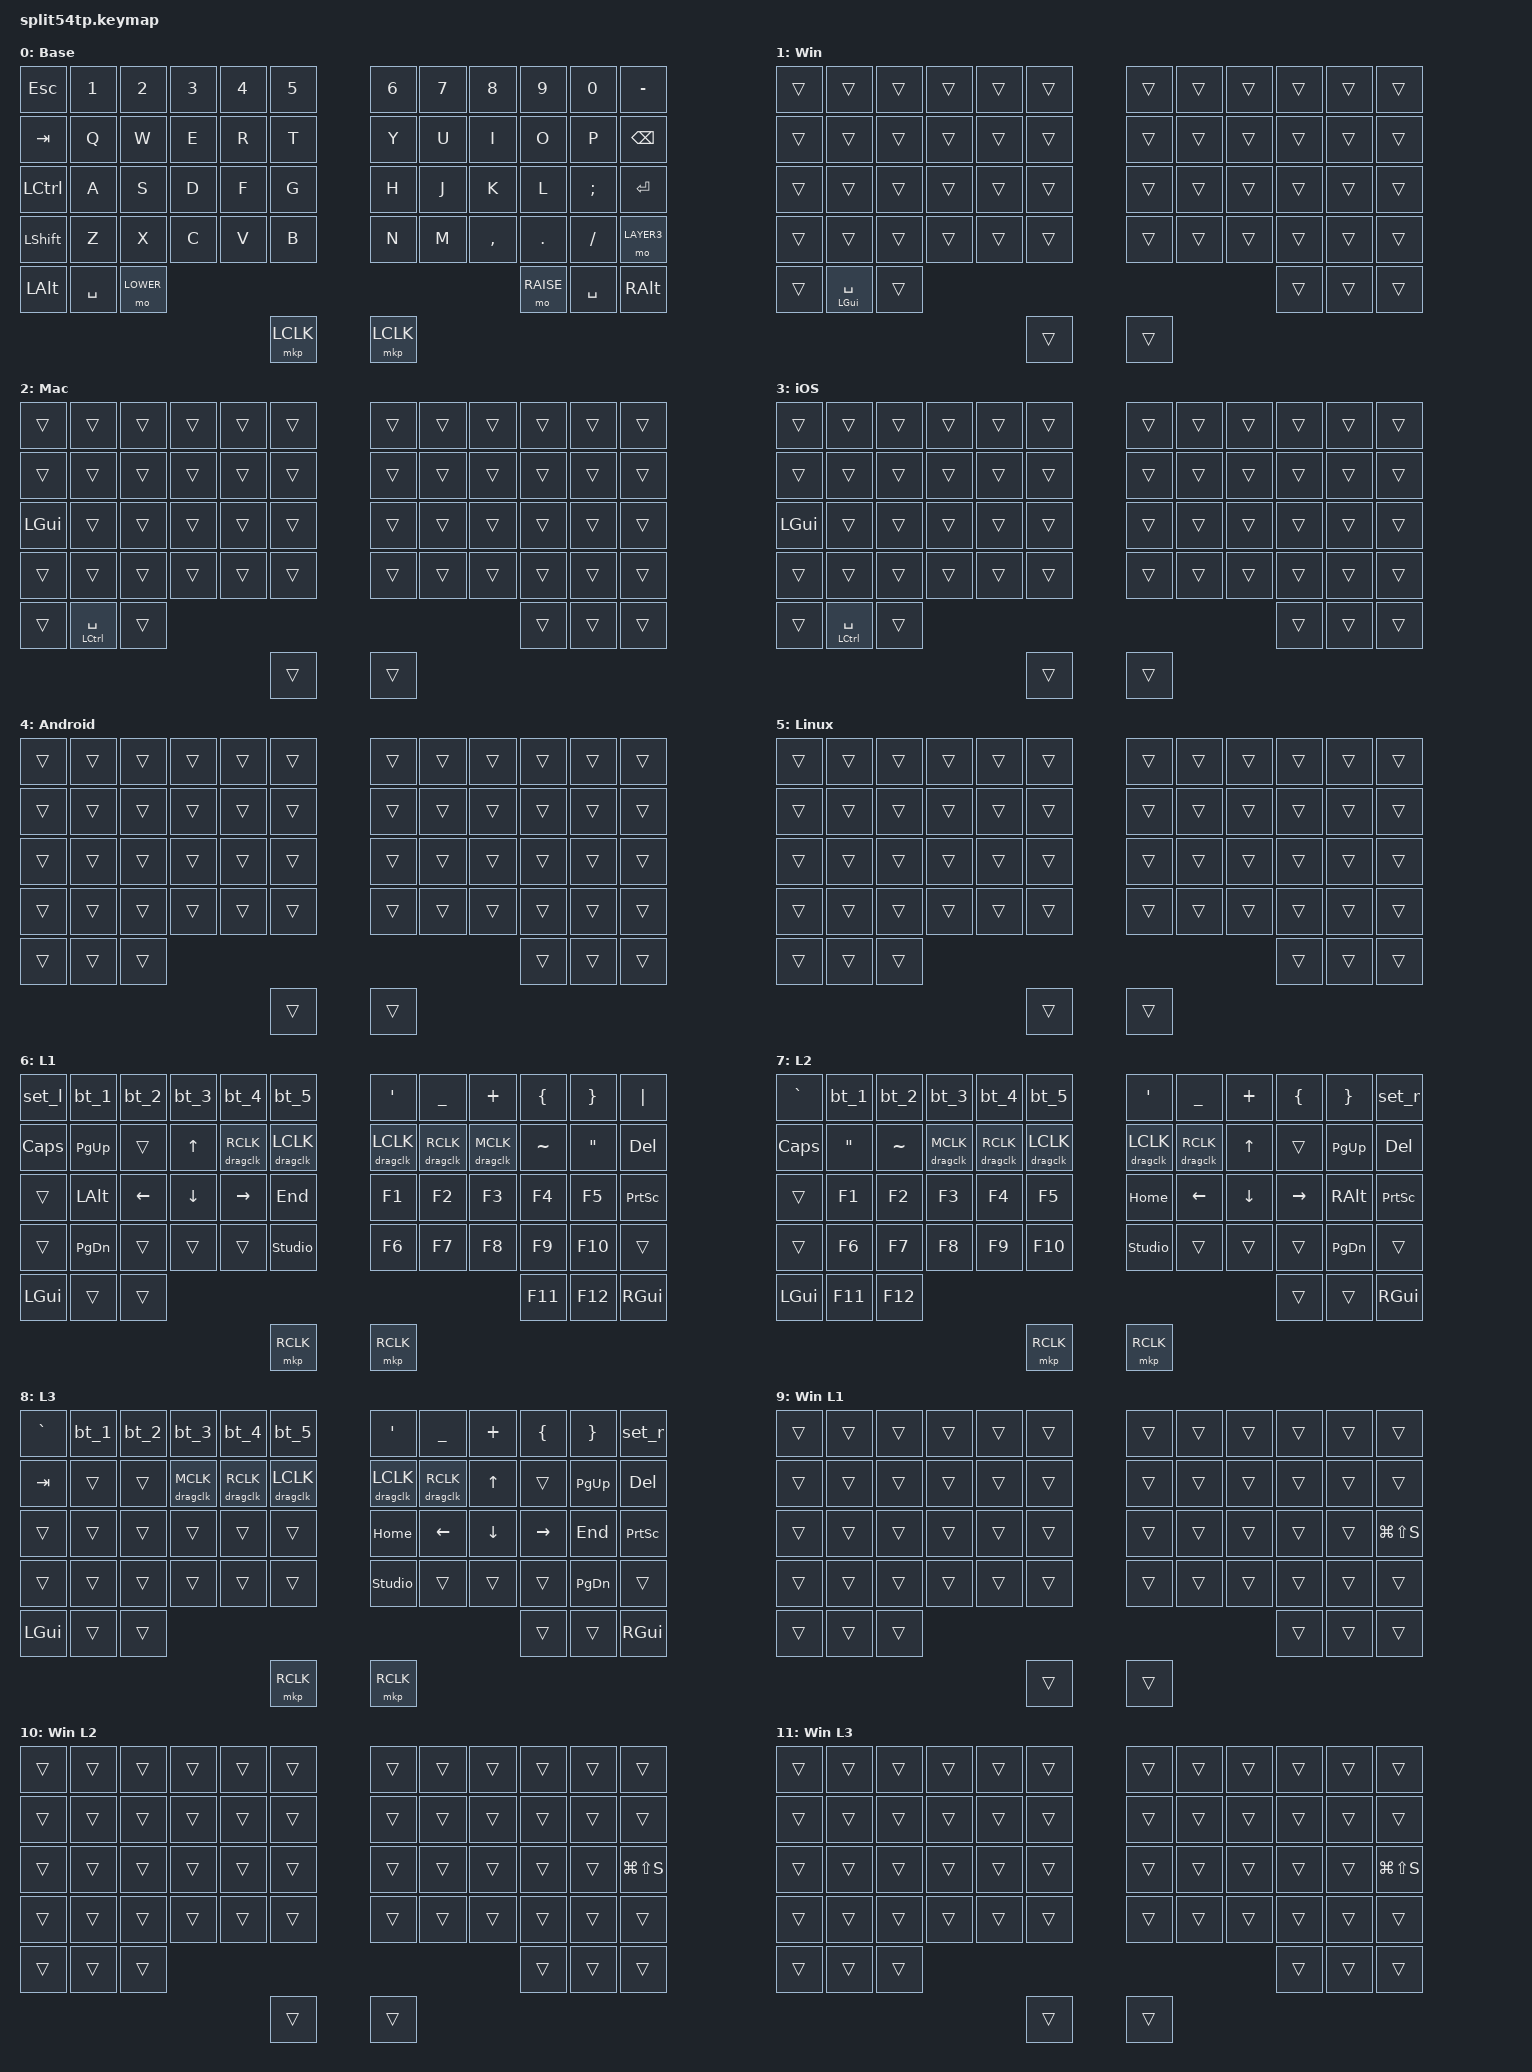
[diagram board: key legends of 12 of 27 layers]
/*
 * split54tp デフォルトキーマップ (US配列 / 手書きレイアウト図準拠)
 * 54キー + ホイールエンコーダのプッシュ2 = 56ポジション
 *
 *  ┌─────┬─────┬─────┬─────┬─────┬─────┐   ┌─────┬─────┬─────┬─────┬─────┬─────┐
 *  │ ESC │  1  │  2  │  3  │  4  │  5  │   │  6  │  7  │  8  │  9  │  0  │  -  │  (2026-11-01: DEL → -。DEL は L1 + BS)
 *  ├─────┼─────┼─────┼─────┼─────┼─────┤   ├─────┼─────┼─────┼─────┼─────┼─────┤
 *  │ TAB │  Q  │  W  │  E  │  R  │  T  │   │  Y  │  U  │  I  │  O  │  P  │ BS  │
 *  ├─────┼─────┼─────┼─────┼─────┼─────┤ ◉ ├─────┼─────┼─────┼─────┼─────┼─────┤  ◉=スティック
 *  │CTRL │  A  │  S  │  D  │  F  │  G  │   │  H  │  J  │  K  │  L  │  ;  │ ENT │
 *  ├─────┼─────┼─────┼─────┼─────┼─────┤ ≡ ├─────┼─────┼─────┼─────┼─────┼─────┤  ≡=スクロールホイール
 *  │SHIFT│  Z  │  X  │  C  │  V  │  B  │   │  N  │  M  │  ,  │  .  │  /  │SHIFT│
 *  └─────┴─────┴─────┼─────┼─────┼─────┤   ├─────┼─────┼─────┼─────┴─────┴─────┘
 *                    │ALT  │SPC  │ L1  │   │ L2  │SPC  │ALT  │
 *                    └─────┴─────┴─────┘   └─────┴─────┴─────┘
 *
 * ★ ZMK Studio 対応ビルドです (右=セントラルのみ)。
 *   https://zmk.studio/ に接続すると、再ビルドなしでキー割当を変更できます。
 *   変更するには、まず &studio_unlock を押してロックを解除します。
 *     L1 + B の位置 … 左半身  (2026-11-15 変更。前は L2 + Tab の位置)
 *     L2 + N の位置 … 右半身  (2026-11-15 変更。前は L2 + BS の位置。L3 + N でも同じ)
 *     L2 の Tab / BS の位置は Del になった (2026-11-15、ユーザー指定)
 *     ゴースト (2026-11-15 配線表から計算、2 キー同時。L1 / L2 の親指はゴーストが立たない位置):
 *       B (Studio解除) が立つのは 1 + D・2 + C、N が立つのは , + 9・0 + K、Tab (Del) は 1 + Z、BS (Del) は / + 0 (どれもふだん同時に押さない)。
 *       B・N・Tab・BS をほかのキーと一緒に押して立つものに、書き換え・ペアリング・BT 消去はない。
 *   ⚠ 2026-11-15 レイヤーの数と並びを変えた (7 → 27 枚)。Studio で保存したことがあれば、Studio の "Restore Stock Settings" を実行すること。
 *   ⚠ 切断するか、Studio上で一定時間操作しないと再びロックされる。
 *     https://zmk.dev/docs/keymaps/behaviors/studio-unlock
 *
 *   ⚠ 一度 Studio でキーマップを保存すると、このファイルへの変更は反映されなくなります。
 *     戻すには Studio の "Restore Stock Settings" を実行してください。
 *     以降、このファイルは「初期値」と「Studioで使えるレイヤー枠」を決めるものになります。
 *
 * ★ ファームウェア書き換え用のキー (2026-08-31 追加 / 2026-11-01 左右とも変更 / 2026-11-04 設定レイヤーへ移動)
 *     設定レイヤーの X (左手だけ) → 左半身をブートローダへ
 *     設定レイヤーの . (右手だけ) → 右半身をブートローダへ
 *   ⚠ キーマップは右で処理するので、左の書き換えにも右の電源と左右の接続が要る。
 *     https://zmk.dev/docs/features/split-keyboards
 *
 * ★ 設定レイヤー (2026-11-04 追加。下の settings_layer)
 *   書き換え・TP 校正・TP 感度・BT 消去・USB / BT 出力の切り替えをまとめた。
 *   片側が使えなくても、もう片側だけで入って設定できるように左右に同じものを置いた。
 *     入る: 左 = L1 + Shift + Esc の位置 / 右 = L2 + Shift + - の位置 (Shift を押していなければ今までどおり ` / |)
 *       ★ 2026-11-15 右 Shift の位置は L3 になった。右手だけなら L2 + L3 (右 Shift の位置) + - (同じ指の動き)
 *     出る: L1 / L2 / 左 Ctrl / Enter のどれかを押す
 *   入ったままになる (&tog)。ほかのキーは何もしない (&none) ので、文字が打てなければ設定レイヤーにいる。
 *   OLED のレイヤー名は "Set"。

 * ★★ チャーリープレックスのゴースト (2026-09-12 実機で確定) ★★
 *
 *   内側親指 RC(5,6) を押している間、sense線5のキー (7/U/J/M) を押すと
 *   ダイオードが直列につながり、sense線6の同じ行 (6/Y/H/N) が
 *   「押された」ことになる。逆に drive線6のキー (9/O/L/.) を押すと
 *   (0/P/;//) が立つ。これは電気的な制約でファームでは直せない。
 *
 *   実害の例: L2 + M → ゴーストで N が立ち、旧配置の &bootloader が発火して
 *             右半身がブートローダに入る (2026-09-12 に3時間を費やした)
 *             L2 + J → ← に加えて H の右クリックが出る (現在も再現する)
 *
 *   【原則】内側親指と併用するレイヤーでは、次の8か所に
 *           破壊的な操作やマウスクリックを置かないこと。
 *             6 / Y / H / N  (右・global col 13)
 *             0 / P / ; / /  (右)
 *           左半身も対称に 5 / T / G / B と同等の位置が該当する。
 *
 *   【ゴースト非対象の安全な位置】(内側親指と併用しても幽霊が立たない)
 *             右: I, BSPC, ,(カンマ), 右Shift
 *           → &bootloader と &studio_unlock はここへ逃がしてある。
 *
 *   rev.6 では親指キーとメイン列の電気的マッピングを見直すこと (最重要課題)。
 *
 *   ★ 2026-09-26 rev.6 で解決: 配線割当を見直し、保持キー併用時のゴーストは
 *     すべて未使用ペアに落ちる (実機で確認)。L1/L2 の &none 退避を撤去し、
 *     ゴースト対策前 (split54tp.keymap.bak4-20260912) の配置に戻した。
 *     &bootloader(L2+BSPC) / &studio_unlock(L2+Shift) の位置は bak4 のまま。
 *     上記の説明は rev.5 の記録として残す。
 *
 *   ZMK公式: リセット系ビヘイビアは「押した側」にだけ作用する (source-specific)。
 *   そのため左右それぞれにキーが必要。コンボにすると常にセントラル(右)側で
 *   実行されてしまうため、通常のキーとして両側に置いている。
 *   https://zmk.dev/docs/keymaps/behaviors/reset
 *
 *   ⚠ これはファームが正常に起動し、キーが反応する場合にのみ使える。
 *     起動しない / 配線ミスで反応しない場合は、XIAO のリセットボタンを
 *     素早く2回押す (ハードウェア側の最後の砦)。
 *
 * エンコーダは横軸のスクロールホイール(マウスホイール方式)。
 * ※ エンコーダへの behavior 割当は ZMK Studio では未対応のため、ここで定義します。
 * 回転はマウスのホイールスクロールとして送出する (&msc SCRL_UP / SCRL_DOWN)。
 * スクロール方向が逆の場合は enc_scroll の bindings を入れ替える。
 */

#include <behaviors.dtsi>
#include <dt-bindings/zmk/keys.h>
#include <dt-bindings/zmk/bt.h>
/*
 * ★ マウススクロールの速度 (既定: 10)
 *   &msc は押下時間に比例して積算する速度ベースの挙動。エンコーダは
 *   press→release が一瞬なので、既定値のままだと積算量がほぼ0になり動かない。
 *   下の scroll_dn / scroll_up マクロのホールド時間とセットで調整する。
 *   https://zmk.dev/docs/keymaps/behaviors/mouse-emulation
 */
#define ZMK_POINTING_DEFAULT_SCRL_VAL 80
#include <dt-bindings/zmk/pointing.h>
#include <dt-bindings/zmk/outputs.h>
#include <dt-bindings/zmk/modifiers.h>

/*
 * ★ 2026-10-31 LPPS の強制キャリブレーション (L2 + / に割当。2026-11-01 に . から移動)
 *   押すと、次に MOTION が来たときにドライバがレジスタ 0x04 に 1 を書く。そのときにスティックに触っていないこと。
 *   セントラル (右) で実行されるので、効くのは右の LPPS だけ。
 *   https://github.com/sekigon-gonnoc/zmk-driver-lpps
 *
 * ★ 2026-11-04 ドライバの &ps_calib をやめ、自作の &tpcalib (押した側の LPPS を校正) に替えた。
 *   設定レイヤーの Z (左) / / (右)。中身はドライバと同じ (lpps_request_write) で、実行する半身だけが違う。
 *   zmk-config の src/behaviors/behavior_tp_calib_local.c。左のファームにも入るので、左も書き直すこと。
 *   そのため lpps-calibration.dtsi は読み込まない。
 */

/*
 * ---- レイヤー構成 ----
 *  ZMKには「BLEプロファイルごとのキーマップ」機能は存在しない。
 *  レイヤーは全プロファイル共通なので、"プロファイル切替と同時にOS用の
 *  ベースレイヤーへ移動する" マクロを組んで等価の運用を実現する。
 *
 *  &to は「デフォルトレイヤー以外を全て無効化」する仕様なので、
 *  OS別レイヤーは差分(修飾キーの入れ替え)だけを書き、
 *  残りは &trans にしてレイヤー0を透過させればよい。
 *  https://zmk.dev/docs/keymaps/behaviors/layers
 */
/*
 * ★ 2026-11-01 OS 別のレイヤーを L1 / L2 より小さい番号に変更。
 *   番号が大きいレイヤーが優先されるので、Mac / iPad が上だと L2 + 左 Space (F11) や
 *   L1 / L2 のホイールが Mac / iPad の設定に隠れる。番号は下の keymap ノードの並びと合わせること。
 *   https://zmk.dev/docs/keymaps
 */
/*
 * ★ 2026-11-15 OS を 5 つに (ユーザー指定: Mac / Windows / iOS (iPad から改名) / Android / Linux、BT も 5 つ)。
 *   形は「共通 + OS ごとの差分」(ユーザーが選択): Base / L1 / L2 / L3 は全 OS 共通の 1 組。
 *   OS ごとに違うキーだけを、その OS のレイヤー (Base の差分) と「OS の L1 / L2 / L3」(L1〜L3 の差分) に書く。
 *   差分のレイヤーは &trans ばかりで、違うキーだけを書く。Studio でも OS ごとに変えられる。
 *   「OS の L1」などは条件付きレイヤー (下の conditional_layers) で、その OS と L1 の両方が有効な間だけ重なる。
 *     https://zmk.dev/docs/keymaps/conditional-layers
 *   BT1〜5 と OS は 1 対 1 (今は。ユーザーは将来、接続先と OS を別に選びたい):
 *     BT1 = Mac / BT2 = Windows / BT3 = iOS / BT4 = Android / BT5 = Linux
 *   OS のレイヤーは Ctrl + 1〜5 (L1 / L2 / L3) とペアリングのキー (設定レイヤー) で切り替わるほか、
 *   選んでいる BT の相手とつながったときにも自動で合わせる (下の os_layers と src/os_layers.c)。
 *   電源を入れた直後は Base だけで、相手とつながると、その OS のレイヤーになる。
 *   番号 (= 下の keymap ノードの並び) を変えたら、split54tp_right.overlay の tp_scroll / tp_drag の layers も直すこと。
 */
#define BASE     0   // 共通の Base (どの OS のレイヤーも重なっていないとき = 電源を入れてから相手とつながるまで)
#define WIN      1   // Windows : 左 Space の長押し → Win (2026-11-15)。ほかは Base のまま
#define MAC      2   // Mac     : 左 CTRL の位置 → CMD、左 Space の長押し → CTRL
#define IOS      3   // iOS     : Mac と同じ配列 (2026-11-15 iPad から改名)
#define ANDROID  4   // Android : 今は差分なし (Base のまま)
#define LINUX    5   // Linux   : 今は差分なし (Base のまま)
#define LOWER    6   // L1
#define RAISE    7   // L2
#define LAYER3   8   // L3 (2026-11-15 右 Shift の位置を押している間。中身は L2 から F1〜F12 を除いたもの)
#define WIN_L1   9   // ここから 23 までは「OS の L1 / L2 / L3」(条件付きレイヤー)
#define WIN_L2  10
#define WIN_L3  11
#define MAC_L1  12
#define MAC_L2  13
#define MAC_L3  14
#define IOS_L1  15
#define IOS_L2  16
#define IOS_L3  17
#define AND_L1  18
#define AND_L2  19
#define AND_L3  20
#define LNX_L1  21
#define LNX_L2  22
#define LNX_L3  23
#define SETENT  24   // L2 + L3 を押している間 (条件付き)。- の位置で設定レイヤーへ (右手だけで入るため。前は L2 + 右 Shift + -)
#define SETTINGS 25  // 設定レイヤー (2026-11-04)。L1〜L3 より上に置き、入っている間は L1〜L3 より優先する
#define DRAG    26   // ★ 2026-11-15 ドラッグ (L1〜L3 のクリックを押している間だけ重なる。中身はすべて &trans)。
                     //   番号は split54tp_right.overlay の tp_drag の layers と合わせること

// &tps_l / &tps_r (TP 感度) の引数 (src/behaviors/behavior_tp_speed.c と合わせる)
#define TPS_DN  0   // 1 段下げる
#define TPS_UP  1   // 1 段上げる
#define TPS_DEF 2   // 既定 (100%) に戻す

/ {
    behaviors {
        /*
         * ---- BLEプロファイル切替 (CTRL + 数字キー) ----
         * ベースの 1/2/3/4 の位置に置く。レイヤー(L1/L2)上で
         *   そのまま押す        → 記号 ( - = [ ] )
         *   CTRLを押しながら    → BLEプロファイル 1〜4 に切替/ペアリング
         * keep-mods は既定の0なので、数字キーを押している間は CTRL を外した報告になる。
         * ただし CTRL を押した時点の「CTRL を押した」という報告は、そのときのホストへもう送られている
         * (2026-11-15 訂正。前は「CTRLはホストへ送出されない」と書いていた)。
         * https://zmk.dev/docs/keymaps/behaviors/mod-morph
         *
         * ZMKは既定で5プロファイルを持つ (右 = セントラルは BT_MAX_PAIRED 6 − 左 1)。
         * ★ 2026-11-15 4 つ → 5 つ全部を使う (5 の位置 = BT5。Ctrl なしは今までどおり \)。
         * https://zmk.dev/docs/features/bluetooth#profiles
         */
        /*
         * プロファイル切替 = BLEプロファイル選択 + OS用ベースレイヤーへ移動
         *   1: Mac  / 2: Windows(会社PC) / 3: iOS / 4: Android / 5: Linux (2026-11-15。前は 3: iPad / 4: 予備 (Windows 配列))
         *
         * ★ 2026-11-15 切り替える前に、元のホストへ「CTRL を離した」を送る
         *   (ユーザー: Windows でスクロールがズームになり、ほかのマウスでも同じ。Windows の再起動で直る)。
         *   ZMK (641514a) はプロファイルを切り替えるとき、押しているキーを全部離した報告を送るが、
         *   app/src/ble.c の zmk_ble_prof_select() が先に active_profile を新しい番号に変えてから知らせるので、
         *   app/src/hog.c は zmk_ble_active_profile_conn() = 新しいホストへ送る。元のホストには
         *   「CTRL を押した」だけが残り、元のホストでは CTRL を押したままに見える (CTRL + ホイール = ズーム)。
         *   そこで、まだ元のホストを向いているうちに LCTRL を離し、wait-ms (30ms) の間に送らせてから切り替える。
         *   このあと指で CTRL を離しても、ZMK は「もう離してある」として何も送らない (app/src/hid.c)。
         *   続けて別の番号へ切り替えるときは、CTRL を押し直す。
         *   CTRL は左 CTRL (BASE) と、Mac / iPad の左 Space 長押し (&ctl_spc LCTRL) の 2 つで、どちらも LCTRL。
         *   https://zmk.dev/docs/keymaps/behaviors/macros
         * ★ 2026-11-21 Mac / iOS の L1 では Cmd + 1〜5 でも切り替える (下の btm_1〜btm_5、ユーザー指定)。
         *   そのため LCTRL に加えて LGUI / RGUI も離してから切り替える (Cmd も元のホストで押したままに見えないように)。
         *   押していない修飾キーを離しても、ZMK は何も送らない (app/src/hid.c が「押されていない」として報告を作らない)。
         */
        prof1_mac: prof1_mac {
            compatible = "zmk,behavior-macro";
            #binding-cells = <0>;
            wait-ms = <30>;
            bindings = <&macro_release &kp LCTRL &kp LGUI &kp RGUI>, <&macro_tap &bt BT_SEL 0 &to MAC>;
        };
        prof2_win: prof2_win {
            compatible = "zmk,behavior-macro";
            #binding-cells = <0>;
            wait-ms = <30>;
            bindings = <&macro_release &kp LCTRL &kp LGUI &kp RGUI>, <&macro_tap &bt BT_SEL 1 &to WIN>;   // 2026-11-15 BASE → WIN
        };
        prof3_ios: prof3_ios {
            compatible = "zmk,behavior-macro";
            #binding-cells = <0>;
            wait-ms = <30>;
            bindings = <&macro_release &kp LCTRL &kp LGUI &kp RGUI>, <&macro_tap &bt BT_SEL 2 &to IOS>;
        };
        prof4_android: prof4_android {
            compatible = "zmk,behavior-macro";
            #binding-cells = <0>;
            wait-ms = <30>;
            bindings = <&macro_release &kp LCTRL &kp LGUI &kp RGUI>, <&macro_tap &bt BT_SEL 3 &to ANDROID>;   // 2026-11-15 予備 (BASE) → Android
        };
        prof5_linux: prof5_linux {
            compatible = "zmk,behavior-macro";
            #binding-cells = <0>;
            wait-ms = <30>;
            bindings = <&macro_release &kp LCTRL &kp LGUI &kp RGUI>, <&macro_tap &bt BT_SEL 4 &to LINUX>;   // 2026-11-15 追加
        };

        /*
         * ★ 2026-11-11 ボタン一つでペアリング (ユーザー指定)。設定レイヤーの 左 1〜4 / 右 6〜9 = BT1〜BT4。
         *   ★ 2026-11-15 BT5 (Linux) を追加: 左 5 / 右 0。
         *   出力を BT にする → その番号を選ぶ → その番号の登録を消す (ペアリング待ちになる) → その OS のレイヤーへ。
         *   &to で設定レイヤーから出る。OLED は「BTn ⚙」(歯車 = ペアリング待ち)。相手の機器でも古い登録を消してからペアリングする。
         *   ⚠ 押すとその番号の登録が消える (ほかの番号と、左右の間の接続は消えない)。
         *   https://zmk.dev/docs/keymaps/behaviors/bluetooth / https://zmk.dev/docs/keymaps/behaviors/outputs
         */
        /*
         * ★ 2026-11-15 ドラッグできるクリック (ユーザー: 「左クリックし続けた状態で TP を触っても全く動かない」)。
         *   L1 / L2 を押している間はスティックがスクロールになる (split54tp_right.overlay の tp_scroll / tp_hscroll) ので、
         *   L1 / L2 のクリックを押したままスティックを倒しても、カーソルが動かなかった。
         *   押している間だけ DRAG レイヤーを重ねてクリックも押したままにし、離したら両方離す。
         *   split54tp_right.overlay の tp_drag (DRAG のときはカーソル) を tp_scroll / tp_hscroll より前に書いてあるので、
         *   ZMK は先に当てはまった tp_drag を使い、tp_scroll / tp_hscroll は使わない (app/src/pointing/input_listener.c)。
         *   ★ 2026-11-21 スクロールは、押したキーと同じ側のスティック = 上下、反対側 = 左右 (tp_hscroll を追加。rev7-修正計画.md 手順 249)。
         *   使い方: &dragclk LCLK / RCLK / MCLK。https://zmk.dev/docs/keymaps/behaviors/macros
         */
        dragclk: dragclk {
            compatible = "zmk,behavior-macro-one-param";
            #binding-cells = <1>;
            wait-ms = <0>;
            tap-ms = <0>;
            bindings
                = <&macro_press &mo DRAG>
                , <&macro_param_1to1>
                , <&macro_press &mkp MACRO_PLACEHOLDER>
                , <&macro_pause_for_release>
                , <&macro_param_1to1>
                , <&macro_release &mkp MACRO_PLACEHOLDER>
                , <&macro_release &mo DRAG>
                ;
        };

        pair1: pair1 {
            compatible = "zmk,behavior-macro";
            #binding-cells = <0>;
            bindings = <&out OUT_BLE>, <&bt BT_SEL 0>, <&bt BT_CLR>, <&to MAC>;
        };
        pair2: pair2 {
            compatible = "zmk,behavior-macro";
            #binding-cells = <0>;
            bindings = <&out OUT_BLE>, <&bt BT_SEL 1>, <&bt BT_CLR>, <&to WIN>;   // 2026-11-15 BASE → WIN
        };
        pair3: pair3 {
            compatible = "zmk,behavior-macro";
            #binding-cells = <0>;
            bindings = <&out OUT_BLE>, <&bt BT_SEL 2>, <&bt BT_CLR>, <&to IOS>;
        };
        pair4: pair4 {
            compatible = "zmk,behavior-macro";
            #binding-cells = <0>;
            bindings = <&out OUT_BLE>, <&bt BT_SEL 3>, <&bt BT_CLR>, <&to ANDROID>;   // 2026-11-15 BASE → ANDROID
        };
        pair5: pair5 {   // 2026-11-15 追加 (BT5 = Linux)
            compatible = "zmk,behavior-macro";
            #binding-cells = <0>;
            bindings = <&out OUT_BLE>, <&bt BT_SEL 4>, <&bt BT_CLR>, <&to LINUX>;
        };

        bt_1: bt_1 {
            compatible = "zmk,behavior-mod-morph";
            #binding-cells = <0>;
            bindings = <&kp MINUS>, <&prof1_mac>;
            mods = <(MOD_LCTL|MOD_RCTL)>;
        };
        bt_2: bt_2 {
            compatible = "zmk,behavior-mod-morph";
            #binding-cells = <0>;
            bindings = <&kp EQUAL>, <&prof2_win>;
            mods = <(MOD_LCTL|MOD_RCTL)>;
        };
        bt_3: bt_3 {
            compatible = "zmk,behavior-mod-morph";
            #binding-cells = <0>;
            bindings = <&kp LBKT>, <&prof3_ios>;
            mods = <(MOD_LCTL|MOD_RCTL)>;
        };
        bt_4: bt_4 {
            compatible = "zmk,behavior-mod-morph";
            #binding-cells = <0>;
            bindings = <&kp RBKT>, <&prof4_android>;
            mods = <(MOD_LCTL|MOD_RCTL)>;
        };
        bt_5: bt_5 {   // 2026-11-15 追加。5 の位置 (Ctrl なしは今までどおり \)
            compatible = "zmk,behavior-mod-morph";
            #binding-cells = <0>;
            bindings = <&kp BSLH>, <&prof5_linux>;
            mods = <(MOD_LCTL|MOD_RCTL)>;
        };

        /*
         * ★ 2026-11-21 Mac / iOS の L1 だけ: Ctrl でも Cmd でも BT を切り替える (ユーザー指定)。
         *   ユーザー: Mac / iOS から他の OS へ切り替えるとき、Ctrl は左 Space の長押しなので L1 と一緒に押すのが手間。
         *   Mac / iOS では左 CTRL の位置が Cmd (LGUI) なので、L1 + Cmd + 1〜5 で切り替えられるようにした。
         *   置くのは mac_l1_layer / ios_l1_layer の 1〜5 の位置だけ (L1 の bt_1〜bt_5 の上に重なる)。
         *   ⚠ Mac / iOS の L1 では Cmd + - = [ ] \ (縮小・拡大・戻る・進むなど) は送れない。L2 / L3 + Cmd + 1〜5 では今までどおり送る
         *     (ユーザーが「L1 だけ変える」を選んだ)。Windows / Android / Linux は今までどおり (Ctrl だけ)。
         *   切り替えの中身は prof1_mac〜prof5_linux と同じ (LCTRL / LGUI / RGUI を離してから切り替える)。
         *   https://zmk.dev/docs/keymaps/behaviors/mod-morph
         */
        btm_1: btm_1 {
            compatible = "zmk,behavior-mod-morph";
            #binding-cells = <0>;
            bindings = <&kp MINUS>, <&prof1_mac>;
            mods = <(MOD_LCTL|MOD_RCTL|MOD_LGUI|MOD_RGUI)>;
        };
        btm_2: btm_2 {
            compatible = "zmk,behavior-mod-morph";
            #binding-cells = <0>;
            bindings = <&kp EQUAL>, <&prof2_win>;
            mods = <(MOD_LCTL|MOD_RCTL|MOD_LGUI|MOD_RGUI)>;
        };
        btm_3: btm_3 {
            compatible = "zmk,behavior-mod-morph";
            #binding-cells = <0>;
            bindings = <&kp LBKT>, <&prof3_ios>;
            mods = <(MOD_LCTL|MOD_RCTL|MOD_LGUI|MOD_RGUI)>;
        };
        btm_4: btm_4 {
            compatible = "zmk,behavior-mod-morph";
            #binding-cells = <0>;
            bindings = <&kp RBKT>, <&prof4_android>;
            mods = <(MOD_LCTL|MOD_RCTL|MOD_LGUI|MOD_RGUI)>;
        };
        btm_5: btm_5 {
            compatible = "zmk,behavior-mod-morph";
            #binding-cells = <0>;
            bindings = <&kp BSLH>, <&prof5_linux>;
            mods = <(MOD_LCTL|MOD_RCTL|MOD_LGUI|MOD_RGUI)>;
        };

        /*
         * ★ 2026-11-01 Mac / iPad の左 Space: 短く押すと Space、約 0.2 秒以上押すと CTRL
         *   Mac / iPad レイヤーは左 CTRL の位置が CMD になり CTRL が無くなるので、ここに置く。
         *   プロファイルの切り替えも、左 Space の長押し + L2 + 1〜4 でできる（L1 は同じ親指なので押せない）。
         *   ★ 2026-11-21 Mac / iOS では L1 + Cmd (左 CTRL の位置) + 1〜5 でも切り替えられる (上の btm_1〜btm_5)。
         *   左 Space を先に押すこと。L2 を先に押すと L2 + 左 Space = F11 になる。
         *   tap-preferred: 判定は時間だけで決まる。他のキーを一緒に押しても CTRL に早変わりしない。
         *   quick-tap-ms: 短く押してすぐ押し直すと Space のまま（押し続ければ連続入力）。
         *   https://zmk.dev/docs/keymaps/behaviors/hold-tap
         * ★ 2026-11-15 Windows の左 Space の長押し = Win にも使う (&ctl_spc LGUI SPACE、ユーザー指定)。名前は ctl_spc のまま。
         *   ⚠ Windows は Win を押して離すだけ (ほかのキーを押さない) とスタートメニューが開く。
         *     左 Space を約 0.2 秒以上押したまま、ほかのキーを押さずに離すと、スタートメニューが開く (Mac の CTRL では何も起きない)。
         */
        ctl_spc: ctl_spc {
            compatible = "zmk,behavior-hold-tap";
            #binding-cells = <2>;
            flavor = "tap-preferred";
            tapping-term-ms = <200>;
            quick-tap-ms = <200>;
            bindings = <&kp>, <&kp>;
        };

        /*
         * ホイール回転 → マウススクロール
         *
         * ⚠ 2026-09-03 実機で判明: bindings に &msc を直接書くと「全く動かない」。
         *   &msc / &mmv は zmk,behavior-input-two-axis の実装で、
         *   「押している間だけ動く」速度ベースの挙動 (time-to-max-speed-ms=300 /
         *   acceleration-exponent=0)。エンコーダの回転は press→release が一瞬なので
         *   積算量がほぼ0になり、ホストへ何も送られない。
         *   (L2 の &rot_kp PG_DN PG_UP はキーイベントなので問題なく動いた)
         *
         *   → マクロで press → wait-ms → release とし、一定時間ホールドさせる。
         *
         * ★ 調整点 (実機で追い込むこと)
         *     動かない        → wait-ms を長くする / SCRL_VAL を上げる
         *     行き過ぎる      → wait-ms を短くする / SCRL_VAL を下げる
         *     速く回すと遅れる → wait-ms を短くし、SCRL_VAL を上げて補う
         *   目安: SCRL_VAL は「毎秒Nクリック」相当。1クリックに 1000/N ms かかる。
         *         SCRL_VAL=80 → 1クリック12.5ms → wait-ms=40 で1ノッチ約3.2クリック。
         *   履歴: 40/40 (約1.6クリック) は「動くが少なすぎる」→ 80 へ (2026-09-03 実機)
         *         rev.6 (CKW12) で 80/40 は「マウスより1ノッチの移動量が大きい」→ wait-ms 20 へ (2026-09-26)
         *
         * https://zmk.dev/docs/keymaps/behaviors/mouse-emulation
         */
        scroll_dn: scroll_dn {
            compatible = "zmk,behavior-macro";
            #binding-cells = <0>;
            wait-ms = <20>;
            tap-ms = <10>;
            bindings = <&macro_press &msc SCRL_DOWN>, <&macro_release &msc SCRL_DOWN>;
        };
        scroll_up: scroll_up {
            compatible = "zmk,behavior-macro";
            #binding-cells = <0>;
            wait-ms = <20>;
            tap-ms = <10>;
            bindings = <&macro_press &msc SCRL_UP>, <&macro_release &msc SCRL_UP>;
        };

        // 公式: https://zmk.dev/docs/keymaps/behaviors/sensor-rotate
        enc_scroll: enc_scroll {
            compatible = "zmk,behavior-sensor-rotate";
            #sensor-binding-cells = <0>;
            bindings = <&scroll_dn>, <&scroll_up>;
        };

        // 参考: キー送出にしたい場合はこちらを sensor-bindings に使う
        rot_kp: rot_kp {
            compatible = "zmk,behavior-sensor-rotate-var";
            #sensor-binding-cells = <2>;
            bindings = <&kp>, <&kp>;
        };

        /*
         * ★ 2026-11-04 設定レイヤーに入るキー (Shift を押しているときだけ入る)
         *   左: L1 + Shift + Esc の位置 / 右: L2 + Shift + - の位置
         *   Shift なしなら今までどおり ` / | を送る。
         *   L1 + Shift + Esc の位置は今まで ~ だった。~ は L2 + Shift + Esc の位置で打てる。
         *   L2 + Shift + - の位置は今までも | (Shift を足しても同じ) だった。
         *   ゴースト: L1 + Shift + Esc は RC(4,0) + RC(0,3) + RC(5,2)。立ちうるのは RC(4,3) で、
         *   使っていない組み合わせ (右も同じ並び)。
         *   https://zmk.dev/docs/keymaps/behaviors/mod-morph
         */
        set_l: set_l {
            compatible = "zmk,behavior-mod-morph";
            #binding-cells = <0>;
            bindings = <&kp GRAVE>, <&tog SETTINGS>;
            mods = <(MOD_LSFT|MOD_RSFT)>;
        };
        set_r: set_r {
            compatible = "zmk,behavior-mod-morph";
            #binding-cells = <0>;
            bindings = <&kp PIPE>, <&tog SETTINGS>;
            mods = <(MOD_LSFT|MOD_RSFT)>;
        };

        /*
         * ★ 2026-11-04 TP 校正 (押した側の LPPS)。ノード名は 8 文字以内 (左で実行させるため)。
         *   src/behaviors/behavior_tp_calib_local.c
         */
        tpcalib: tpcalib {
            compatible = "zmk,behavior-tp-calib-local";
            #binding-cells = <0>;
            display-name = "TP Calibrate";
        };

        /*
         * ★ 2026-11-11 TP 復旧 (試し)。押した側の LPPS に、ドライバと同じ読み取り (3 バイト + バスを閉じる 1 バイト) を送り、
         *   結果を押した側の OLED の TP の行に 10 秒出す (「FIX 前>後 ok」など)。設定レイヤーの F (左) / J (右)。
         *   電源を入れたまま置くと TP が止まり、LPPS の電源を切るまで戻らないことがある (keyboard-project/docs/rev7-修正計画.md 手順 161〜163)。
         *   止まったときにこれで戻るかを見るためのもの。ノード名は 8 文字以内 (左で実行させるため)。
         *   src/behaviors/behavior_tp_fix.c
         */
        tpfix: tpfix {
            compatible = "zmk,behavior-tp-fix";
            #binding-cells = <0>;
            display-name = "TP Fix";
        };

        /*
         * ★ 2026-11-04 TP 感度 (左右別)。&tps_l TPS_DN などで使う。
         *   段は split54tp.dtsi の tp_speed_l / tp_speed_r (25〜300%、13 段、既定 100%)。
         *   src/behaviors/behavior_tp_speed.c
         */
        tps_l: tps_l {
            compatible = "zmk,behavior-tp-speed";
            #binding-cells = <1>;
            processor = <&tp_speed_l>;
            display-name = "TP Speed L";
        };
        tps_r: tps_r {
            compatible = "zmk,behavior-tp-speed";
            #binding-cells = <1>;
            processor = <&tp_speed_r>;
            display-name = "TP Speed R";
        };
        /* ★ 2026-11-11 スクロールの速さ (L1 / L2 + スティック、左右共通)。段は split54tp.dtsi の tp_scroll_speed (0.5〜12.5%、10 段、既定 2%) */
        tps_s: tps_s {
            compatible = "zmk,behavior-tp-speed";
            #binding-cells = <1>;
            processor = <&tp_scroll_speed>;
            display-name = "Scroll Speed";
        };

        /*
         * ★ 2026-11-15 エンコーダ (ホイール) のスクロールの速さ (左右共通。ユーザー: 設定レイヤーで変えたい、今の値を OLED に出したい)
         *   段は split54tp.dtsi の enc_scroll_speed (1 ノッチあたり 1/5〜4 目盛り、9 段、既定 1 = 今まで)。
         *   設定レイヤーでホイールを回すと 1 段ずつ変わる (&enc_spd)。ホイールの押し込み = 既定に戻す。
         *   向きは L1 の音量と同じ: 下へスクロールする向き (音量を上げる向き) = 速く。OLED の下の行の W の数字が段。
         *   ホイールの回転はキーの配線を通らないので、回してもゴーストは立たない。
         *   ホイールの押し込みに落ちるゴースト (配線表から計算): 左 1 + T・2 + F / 右 0 + Y・9 + J (既定に戻るだけ)。
         *   ノード名は 8 文字以内にしておく (ほかの tps_* と同じ)。
         */
        tps_w: tps_w {
            compatible = "zmk,behavior-tp-speed";
            #binding-cells = <1>;
            processor = <&enc_scroll_speed>;
            display-name = "Wheel Speed";
        };
        enc_spd: enc_spd {
            compatible = "zmk,behavior-sensor-rotate";
            #sensor-binding-cells = <0>;
            bindings = <&tps_w TPS_UP>, <&tps_w TPS_DN>;
        };
    };

    /*
     * ★ 2026-11-15 OS ごとの L1 / L2 / L3 (差分のレイヤー) を、その OS と L1〜L3 の両方が有効な間だけ重ねる。
     *   ZMK の条件付きレイヤー: if-layers がすべて有効な間だけ then-layer が有効になる。
     *   https://zmk.dev/docs/keymaps/conditional-layers
     */
    conditional_layers {
        compatible = "zmk,conditional-layers";
        win_l1 { if-layers = <WIN LOWER>; then-layer = <WIN_L1>; };
        win_l2 { if-layers = <WIN RAISE>; then-layer = <WIN_L2>; };
        win_l3 { if-layers = <WIN LAYER3>; then-layer = <WIN_L3>; };
        mac_l1 { if-layers = <MAC LOWER>; then-layer = <MAC_L1>; };
        mac_l2 { if-layers = <MAC RAISE>; then-layer = <MAC_L2>; };
        mac_l3 { if-layers = <MAC LAYER3>; then-layer = <MAC_L3>; };
        ios_l1 { if-layers = <IOS LOWER>; then-layer = <IOS_L1>; };
        ios_l2 { if-layers = <IOS RAISE>; then-layer = <IOS_L2>; };
        ios_l3 { if-layers = <IOS LAYER3>; then-layer = <IOS_L3>; };
        and_l1 { if-layers = <ANDROID LOWER>; then-layer = <AND_L1>; };
        and_l2 { if-layers = <ANDROID RAISE>; then-layer = <AND_L2>; };
        and_l3 { if-layers = <ANDROID LAYER3>; then-layer = <AND_L3>; };
        lnx_l1 { if-layers = <LINUX LOWER>; then-layer = <LNX_L1>; };
        lnx_l2 { if-layers = <LINUX RAISE>; then-layer = <LNX_L2>; };
        lnx_l3 { if-layers = <LINUX LAYER3>; then-layer = <LNX_L3>; };
        /* L2 + L3 → - の位置で設定レイヤーへ (右手だけで入るため。setent_layer) */
        set_entry { if-layers = <RAISE LAYER3>; then-layer = <SETENT>; };
    };

    /*
     * ★ 2026-11-15 BT のプロファイル (0 から) ごとの OS のレイヤー。src/os_layers.c が使う。
     *   選んでいる BT の相手とつながったとき (電源を入れた後も)、その OS のレイヤーになっていなければ合わせる。
     *   ほかの OS のレイヤーだけを外し、L1〜L3・設定レイヤーなどは触らない。出力が USB のときは何もしない。
     *   並びは prof1_mac〜prof5_linux と合わせる: BT1 Mac / BT2 Windows / BT3 iOS / BT4 Android / BT5 Linux。
     *   将来、接続先と OS を別に選べるようにするとき (ユーザーの希望) は、ここを入り口にする。
     */
    os_layers {
        compatible = "zmk,split54tp-os-layers";
        profile-layers = <MAC WIN IOS ANDROID LINUX>;
    };

    keymap {
        compatible = "zmk,keymap";

        default_layer {
            display-name = "Base";
            bindings = <
&kp ESC    &kp N1  &kp N2  &kp N3  &kp N4  &kp N5        &kp N6  &kp N7  &kp N8     &kp N9   &kp N0    &kp MINUS
&kp TAB    &kp Q   &kp W   &kp E   &kp R   &kp T         &kp Y   &kp U   &kp I      &kp O    &kp P     &kp BSPC
&kp LCTRL  &kp A   &kp S   &kp D   &kp F   &kp G         &kp H   &kp J   &kp K      &kp L    &kp SEMI  &kp ENTER
&kp LSHFT  &kp Z   &kp X   &kp C   &kp V   &kp B         &kp N   &kp M   &kp COMMA  &kp DOT  &kp FSLH  &mo LAYER3   // ★ 2026-11-15 右 Shift の位置 = L3 (ユーザー指定。右 Shift はなくなった)
                           &kp LALT  &kp SPACE  &mo LOWER     &mo RAISE  &kp SPACE  &kp RALT
&mkp LCLK                                                                     &mkp LCLK   // ホイールのプッシュ = 左クリック (2026-11-01)
            >;
            sensor-bindings = <&enc_scroll &enc_scroll>;
        };

        /*
         * ★ 2026-11-15 Windows (BT2)。左 Space の長押し = Win (ユーザー指定)。ほかは Base のまま。
         *   ⚠ 長押しのまま何も押さずに離すとスタートメニューが開く (上の ctl_spc の説明)。
         */
        win_layer {
            display-name = "Win";
            bindings = <
            &trans    &trans    &trans    &trans    &trans    &trans    &trans    &trans    &trans    &trans    &trans    &trans      // num
            &trans    &trans    &trans    &trans    &trans    &trans    &trans    &trans    &trans    &trans    &trans    &trans      // upper
            &trans    &trans    &trans    &trans    &trans    &trans    &trans    &trans    &trans    &trans    &trans    &trans      // home
            &trans    &trans    &trans    &trans    &trans    &trans    &trans    &trans    &trans    &trans    &trans    &trans      // lower
            &trans    &ctl_spc LGUI SPACE    &trans    &trans    &trans    &trans      // thumb: 左Space の長押し = Win
            &trans    &trans      // ホイールのプッシュ
            >;
        };

        mac_layer {
            display-name = "Mac";
            /* Macの修飾キー: 左CTRLの位置→CMD / 左Spaceの長押し→CTRL。他は &trans でレイヤー0を透過 */
            bindings = <
            &trans    &trans    &trans    &trans    &trans    &trans    &trans    &trans    &trans    &trans    &trans    &trans      // num
            &trans    &trans    &trans    &trans    &trans    &trans    &trans    &trans    &trans    &trans    &trans    &trans      // upper
            &kp LGUI  &trans    &trans    &trans    &trans    &trans    &trans    &trans    &trans    &trans    &trans    &trans      // home : 左CTRLの位置 → CMD(GUI)
            &trans    &trans    &trans    &trans    &trans    &trans    &trans    &trans    &trans    &trans    &trans    &trans      // lower
            &trans    &ctl_spc LCTRL SPACE    &trans    &trans    &trans    &trans      // thumb: 外側は LALT(=Opt) のまま透過。左Space の長押し = CTRL
            &trans    &trans      // ホイールのプッシュ
            >;
            sensor-bindings = <&enc_scroll &enc_scroll>;
        };

        ios_layer {
            display-name = "iOS";   // ★ 2026-11-15 iPad → iOS に改名 (ユーザー指定)。src/display/status_screen.c の MAC_LAYER_NAMES と合わせる
            /* iPadOSもCMD系。中身はMacと同じだが、将来分けられるよう別レイヤーにしてある */
            bindings = <
            &trans    &trans    &trans    &trans    &trans    &trans    &trans    &trans    &trans    &trans    &trans    &trans      // num
            &trans    &trans    &trans    &trans    &trans    &trans    &trans    &trans    &trans    &trans    &trans    &trans      // upper
            &kp LGUI  &trans    &trans    &trans    &trans    &trans    &trans    &trans    &trans    &trans    &trans    &trans      // home : 左CTRLの位置 → CMD(GUI)
            &trans    &trans    &trans    &trans    &trans    &trans    &trans    &trans    &trans    &trans    &trans    &trans      // lower
            &trans    &ctl_spc LCTRL SPACE    &trans    &trans    &trans    &trans      // thumb: 外側は LALT(=Opt) のまま透過。左Space の長押し = CTRL
            &trans    &trans      // ホイールのプッシュ
            >;
            sensor-bindings = <&enc_scroll &enc_scroll>;
        };

        /* ★ 2026-11-15 Android (BT4)。今は差分なし (Base のまま)。変えたいキーだけをここに書く */
        android_layer {
            display-name = "Android";
            bindings = <
            &trans    &trans    &trans    &trans    &trans    &trans    &trans    &trans    &trans    &trans    &trans    &trans      // num
            &trans    &trans    &trans    &trans    &trans    &trans    &trans    &trans    &trans    &trans    &trans    &trans      // upper
            &trans    &trans    &trans    &trans    &trans    &trans    &trans    &trans    &trans    &trans    &trans    &trans      // home
            &trans    &trans    &trans    &trans    &trans    &trans    &trans    &trans    &trans    &trans    &trans    &trans      // lower
            &trans    &trans    &trans    &trans    &trans    &trans      // thumb
            &trans    &trans      // ホイールのプッシュ
            >;
        };

        /* ★ 2026-11-15 Linux (BT5)。今は差分なし (Base のまま)。変えたいキーだけをここに書く */
        linux_layer {
            display-name = "Linux";
            bindings = <
            &trans    &trans    &trans    &trans    &trans    &trans    &trans    &trans    &trans    &trans    &trans    &trans      // num
            &trans    &trans    &trans    &trans    &trans    &trans    &trans    &trans    &trans    &trans    &trans    &trans      // upper
            &trans    &trans    &trans    &trans    &trans    &trans    &trans    &trans    &trans    &trans    &trans    &trans      // home
            &trans    &trans    &trans    &trans    &trans    &trans    &trans    &trans    &trans    &trans    &trans    &trans      // lower
            &trans    &trans    &trans    &trans    &trans    &trans      // thumb
            &trans    &trans      // ホイールのプッシュ
            >;
        };

        lower_layer {
            display-name = "L1";   // OLED の表示 (2026-11-01)
            /*
             * ★ 2026-11-11 (ユーザー指定) PgUp / PgDn を Home・End の上下へ: L1 は Q = PgUp・Z = PgDn (左)、L2 は P = PgUp・/ = PgDn (右)。
             *   もとの PgUp の位置 (L1 の T / L2 の Y) は左クリック。もとの PgDn の位置 (L1 の B / L2 の N) は Base と同じ (&trans)。
             *   ゴースト (配線表から計算): L1 + 左 Shift + Q → A (Home) / L2 + 右 Shift + P → ; (End) が立つ。
             *     Shift + PgUp (範囲選択) は、反対側の Shift で押すこと (左右の間ではゴーストは立たない)。
             *   前からあるもの: L2 + 右 Shift + U (右クリック。2026-11-11 (2 回目) までは左クリック) → K (↓)、L1 + 左 Shift + R (右クリック) → D (↓)。
             *   L1 / L2 を押している間、押したキーと同じ側のスティックは上下、反対側は左右スクロールになる
             *   (L1 = 左が上下・右が左右、L2 = 右が上下・左が左右。split54tp_right.overlay の tp_scroll / tp_hscroll)。
             *   ★ 2026-11-21 前は左右とも上下スクロールだった (rev7-修正計画.md 手順 249)。
             * ★ 2026-11-11 (2 回目、ユーザー指定) クリックの並べ替え:
             *   L1 右: 左クリック U → Y (F1 の上)、右クリック O → U (もとの左クリックの場所)。O は Base と同じ (&trans)。
             *   L2 左: 左クリック W → T (F5 の上)。W は Base と同じ。/ L2 右: 右クリック O → U (← の上)。O は Base と同じ。
             *   これで「L1 の右 Y U I」と「L2 の左 T R E」が左右対称 (左・右・中クリック) になる。
             *   ★ 2026-11-11 (3 回目、ユーザー指定) L1 の左 W (PgUp の右) の左クリックを削除 → Base と同じ。L1 の左のクリックは T (左)・R (右)。
             *   ゴースト (配線表から計算): Shift / Ctrl + 新しいクリックの場所では立たない。
             *     立つのはめったに押さない組み合わせだけ: L2 + U (右クリック) + O → Y (左クリック)、L2 + 4 + 左ホイール押し → T (左クリック)、
             *     L1 + 7 + 右ホイール押し → Y (左クリック)、L1 + 7 + M (F7) → U (右クリック) など。
             * ★ 2026-11-15 L1 / L2 のクリック (左・右・中) を &mkp → &dragclk に (ドラッグできるように)。押している間は DRAG レイヤーが
             *   重なり、スティックはスクロールではなくカーソルになる。ホイールのプッシュ (右クリック) は &mkp のまま。
             * ★ 2026-11-18 (ユーザー指定) L1 の A の位置 (Home) → 左 Alt (矢印 S E D F と一緒に押す)。L1 の Home はなくなった (L2 / L3 の H にある)。
             *   ~ と " を L1 / L2 の空きへ (ユーザー指定。位置は Claude が決めた): L1 = O が ~・P が " / L2 = W が ~・Q が " (左右対称 = 同じ指)。
             *   ゴースト (配線表から計算): O・P・Q・W は、ほかのどのキーと 2 つ同時に押してもゴーストが立たず、ほかの 2 キーで立つこともない。
             *   左 Alt (A) について: L1 + Alt + ← / ↓ / → / ↑ だけなら立たない。⚠ L1 + Alt + Shift + ← (S) と L1 + Alt + ← + ↓ は
             *   3 の位置 ([) が立つ (Mac では Option+Shift+[ で ” が入る)。前からの L1 + Shift + PgUp (Q) → A の位置は、Home ではなく Alt になった。
             */
            bindings = <
&set_l         &bt_1          &bt_2          &bt_3          &bt_4          &bt_5            &kp SQT        &kp UNDER      &kp PLUS       &kp LBRC       &kp RBRC       &kp PIPE   // 記号 (L1/L2共通)  ` - = [ ] \  |  ' _ + { } |   ★ 2026-11-04 Esc の位置 = Shift と一緒に押すと設定レイヤーへ (Shift なしは `)。★ 2026-11-15 5 の位置 = Ctrl と一緒に押すと BT5 (Linux)。Ctrl なしは \ のまま
&kp CAPS       &kp PG_UP      &trans         &kp UP         &dragclk RCLK  &dragclk LCLK    &dragclk LCLK  &dragclk RCLK  &dragclk MCLK  &kp TILDE      &kp DQT        &kp DEL   // ★ 2026-11-18 O=~ P=" (ユーザー指定「L1/L2 の空きに」)。左: Tab の位置=CapsLock Q=PgUp E=↑ R=右クリック T=左クリック (2026-11-11 T の PgUp を Q へ、T は左クリック。(3 回目) W の左クリックを削除 = Base と同じ)  /  右: Y=左クリック U=右クリック I=中クリック、BS の位置=DEL (2026-11-11 (2 回目) 左クリックを U から Y (F1 の上) へ、右クリックを O から U へ。O は Base と同じ)
&trans         &kp LALT       &kp LEFT       &kp DOWN       &kp RIGHT      &kp END          &kp F1         &kp F2         &kp F3         &kp F4         &kp F5         &kp PSCRN   // 左: A=左 Alt (2026-11-18、ユーザー指定。前は Home) S← D↓ F→ G=End  /  右: F1-F5、Enter の位置=PrtSc (2026-11-01。2026-11-15 から OS ごとの差分レイヤーで差し替え)
&trans         &kp PG_DN      &trans         &trans         &trans         &studio_unlock   &kp F6         &kp F7         &kp F8         &kp F9         &kp F10        &trans   // 左: Z=PgDn (2026-11-11 B から Home の下へ) B=Studio解除 (2026-11-15、ユーザー指定。前は L2 + Tab の位置)  /  右: F6-F10 (2026-11-01)。X の書き換えは設定レイヤーへ移した (2026-11-04)
                                               &kp LGUI       &trans         &trans           &kp F11        &kp F12        &kp RGUI   // thumb: 外側=GUI(Win/Cmd)。左=左GUI、右=右GUI / L2 の位置=F11 右Space=F12 (2026-11-01)
&mkp RCLK                                                                                             &mkp RCLK   // ホイールのプッシュ = 右クリック (2026-11-01)
            >;
            // 下位レイヤーではホイールを音量に
            sensor-bindings = <&rot_kp C_VOL_UP C_VOL_DN &rot_kp C_VOL_UP C_VOL_DN>;
        };

        raise_layer {
            display-name = "L2";   // OLED の表示 (2026-11-01)
            bindings = <
&kp GRAVE      &bt_1          &bt_2          &bt_3          &bt_4          &bt_5            &kp SQT        &kp UNDER      &kp PLUS       &kp LBRC       &kp RBRC       &set_r     // 記号 (L1と同一)。★ 2026-11-04 - の位置 = Shift と一緒に押すと設定レイヤーへ (Shift なしは |)。★ 2026-11-15 5 の位置 = Ctrl と一緒に押すと BT5
&kp CAPS       &kp DQT        &kp TILDE      &dragclk MCLK  &dragclk RCLK  &dragclk LCLK      &dragclk LCLK  &dragclk RCLK  &kp UP         &trans         &kp PG_UP      &kp DEL   // ★ 2026-11-18 (ユーザー指定) 左: Tab の位置=CapsLock (前は Del。Del は BS の位置に残る) Q=" W=~ (L1 の P / O と左右対称)。(前の記録) 左: Tab の位置=Del (2026-11-15、ユーザー指定。前は Studio解除) E=中クリック R=右クリック T=左クリック (2026-11-11 (2 回目) 左クリックを W から T (F5 の上) へ。W は Base と同じ。L1 の右 Y U I と左右対称) / 右: Y=左クリック (2026-11-11 PgUp から) U=右クリック (2026-11-11 (2 回目) ← の上。O から) I=↑ P=PgUp (2026-11-11 Y から) BS の位置=Del (2026-11-15。前は Studio解除)。O は Base と同じ。Q〜R の出力の切り替え・BT 消去は設定レイヤーへ移した (2026-11-04)
&trans         &kp F1         &kp F2         &kp F3         &kp F4         &kp F5           &kp HOME       &kp LEFT       &kp DOWN       &kp RIGHT      &kp RALT       &kp PSCRN   // 左: F1-F5 (2026-11-01)  /  右: H=Home J← K↓ L→ ;=右 Alt (2026-11-18、ユーザー指定。前は End。L2 の End はなくなった = L1 の G / L3 の ; にある。ゴースト (計算): L2 + 右 Alt + 矢印 (+ 左 Shift) では立たない) Enter の位置=PrtSc (OS ごとの差分レイヤーで差し替え。2026-11-15)
&trans         &kp F6         &kp F7         &kp F8         &kp F9         &kp F10          &studio_unlock &trans         &trans         &trans         &kp PG_DN      &trans   // 左: F6-F10 / 右: N=Studio解除 (2026-11-15、ユーザー指定) /=PgDn (2026-11-11 N から End の下へ)。. の書き換え・/ の TP 校正は設定レイヤーへ移した (2026-11-04)
                                               &kp LGUI       &kp F11        &kp F12          &trans         &trans         &kp RGUI   // thumb: 外側=GUI(Win/Cmd)。左=左GUI、右=右GUI / 左Space=F11 L1 の位置=F12 (2026-11-01)
&mkp RCLK                                                                                             &mkp RCLK   // ホイールのプッシュ = 右クリック (2026-11-01)
            >;
            // 上位レイヤーではホイールを水平スクロールに
            sensor-bindings = <&rot_kp PG_DN PG_UP &rot_kp PG_DN PG_UP>;
        };

        /*
         * ★ 2026-11-15 L3 (LAYER3 = 8、ユーザー指定)。Base の右 Shift の位置を押している間。
         *   中身は L2 のコピーから F1〜F12 を除いたもの (除いた所は &trans = Base と同じ)。
         *   ★ 2026-11-18 L2 と違う所 (ユーザー指定): Tab の位置 = Tab (L2 は CapsLock)。L2 で変えた ; (右 Alt) と Q W (" ~) は L3 では変えていない (; = End のまま)。
         *   スティックは L2 と同じく、右 = 上下スクロール、左 = 左右スクロール (split54tp_right.overlay の tp_scroll / tp_hscroll)。
         *   ★ 2026-11-21 前は左右とも上下スクロールだった (rev7-修正計画.md 手順 249)。
         *   - の位置は L2 と同じ &set_r: 左 Shift と一緒に押すと設定レイヤーへ。
         *   右手だけで入るときは L2 + L3 (右 Shift の位置) + - (下の setent_layer)。前の L2 + 右 Shift + - と同じ指の動き。
         *   右 Shift はなくなったので、Shift は左 Shift だけ。
         *   ゴースト (配線表から計算): 右 Shift の位置は、ほかのどのキーと同時に押してもゴーストが立たない (L1 / L2 の親指と同じ)。
         */
        layer3_layer {
            display-name = "L3";
            bindings = <
&kp GRAVE      &bt_1          &bt_2          &bt_3          &bt_4          &bt_5          &kp SQT        &kp UNDER      &kp PLUS       &kp LBRC       &kp RBRC       &set_r   // L2 と同じ
&kp TAB        &trans         &trans         &dragclk MCLK  &dragclk RCLK  &dragclk LCLK  &dragclk LCLK  &dragclk RCLK  &kp UP         &trans         &kp PG_UP      &kp DEL   // ★ 2026-11-18 (ユーザー指定) Tab の位置=Tab (前は Del)。L2 の Q W の " ~ は入れていない (ユーザー指定は L1 / L2)。ほかは L2 と同じ
&trans         &trans         &trans         &trans         &trans         &trans         &kp HOME       &kp LEFT       &kp DOWN       &kp RIGHT      &kp END        &kp PSCRN   // 左: F1-F5 を除いた (Base と同じ) / 右: L2 と同じ
&trans         &trans         &trans         &trans         &trans         &trans         &studio_unlock &trans         &trans         &trans         &kp PG_DN      &trans   // 左: F6-F10 を除いた / 右: L2 と同じ (N=Studio解除)。右 Shift の位置 = L3 を押しているキー
                                             &kp LGUI       &trans         &trans         &trans         &trans         &kp RGUI   // thumb: L2 の F11 (左Space) / F12 (L1 の位置) を除いた (Base と同じ)
&mkp RCLK                                                                                             &mkp RCLK   // ホイールのプッシュ = 右クリック (L2 と同じ)
            >;
            sensor-bindings = <&rot_kp PG_DN PG_UP &rot_kp PG_DN PG_UP>;   // L2 と同じ
        };

        /*
         * ★ 2026-11-15 OS ごとの L1 / L2 / L3 (差分。条件付きレイヤー: その OS と L1〜L3 の両方が有効な間だけ重なる)。
         *   ユーザー指定: 「各プロファイルに Base / L1 / L2 / L3、設定レイヤーは共通」→ 形は「共通 + OS ごとの差分」(ユーザーが選択)。
         *   違うキーだけを書く。今は PrtSc (L1〜L3 の Enter の位置) だけ (ユーザー指定「範囲を選んで撮る」):
         *     Mac = Cmd+Shift+5 / Windows = Win+Shift+S / iOS = Cmd+Shift+4 / Android・Linux = PrtSc (共通の &kp PSCRN)
         *     https://support.apple.com/en-us/102646 (Mac) / https://support.microsoft.com/help/13776 (Windows)
         *   OLED のレイヤー名は 7 文字まで (左へ送る形の都合、include/split54tp/status_sync.h)。
         */
        win_l1_layer {
            display-name = "Win L1";
            bindings = <
&trans         &trans         &trans         &trans         &trans         &trans         &trans         &trans         &trans         &trans         &trans         &trans
&trans         &trans         &trans         &trans         &trans         &trans         &trans         &trans         &trans         &trans         &trans         &trans
&trans         &trans         &trans         &trans         &trans         &trans         &trans         &trans         &trans         &trans         &trans         &kp LG(LS(S))   // Enter の位置 = PrtSc → Windows: Win+Shift+S (切り取り領域)
&trans         &trans         &trans         &trans         &trans         &trans         &trans         &trans         &trans         &trans         &trans         &trans
                                             &trans         &trans         &trans         &trans         &trans         &trans
&trans                                                                                                &trans   // ホイールのプッシュ
            >;
        };

        win_l2_layer {
            display-name = "Win L2";
            bindings = <
&trans         &trans         &trans         &trans         &trans         &trans         &trans         &trans         &trans         &trans         &trans         &trans
&trans         &trans         &trans         &trans         &trans         &trans         &trans         &trans         &trans         &trans         &trans         &trans
&trans         &trans         &trans         &trans         &trans         &trans         &trans         &trans         &trans         &trans         &trans         &kp LG(LS(S))   // Enter の位置 = PrtSc → Windows: Win+Shift+S (切り取り領域)
&trans         &trans         &trans         &trans         &trans         &trans         &trans         &trans         &trans         &trans         &trans         &trans
                                             &trans         &trans         &trans         &trans         &trans         &trans
&trans                                                                                                &trans   // ホイールのプッシュ
            >;
        };

        win_l3_layer {
            display-name = "Win L3";
            bindings = <
&trans         &trans         &trans         &trans         &trans         &trans         &trans         &trans         &trans         &trans         &trans         &trans
&trans         &trans         &trans         &trans         &trans         &trans         &trans         &trans         &trans         &trans         &trans         &trans
&trans         &trans         &trans         &trans         &trans         &trans         &trans         &trans         &trans         &trans         &trans         &kp LG(LS(S))   // Enter の位置 = PrtSc → Windows: Win+Shift+S (切り取り領域)
&trans         &trans         &trans         &trans         &trans         &trans         &trans         &trans         &trans         &trans         &trans         &trans
                                             &trans         &trans         &trans         &trans         &trans         &trans
&trans                                                                                                &trans   // ホイールのプッシュ
            >;
        };

        mac_l1_layer {
            display-name = "Mac L1";
            bindings = <
&trans         &btm_1         &btm_2         &btm_3         &btm_4         &btm_5         &trans         &trans         &trans         &trans         &trans         &trans   // ★ 2026-11-21 1〜5 = Ctrl / Cmd + で BT1〜5 (btm_1〜btm_5)
&trans         &trans         &trans         &trans         &trans         &trans         &trans         &trans         &trans         &trans         &trans         &trans
&trans         &trans         &trans         &trans         &trans         &trans         &trans         &trans         &trans         &trans         &trans         &kp LG(LS(N5))   // Enter の位置 = PrtSc → Mac: Cmd+Shift+5 (撮り方を選ぶ画面)
&trans         &trans         &trans         &trans         &trans         &trans         &trans         &trans         &trans         &trans         &trans         &trans
                                             &trans         &trans         &trans         &trans         &trans         &trans
&trans                                                                                                &trans   // ホイールのプッシュ
            >;
        };

        mac_l2_layer {
            display-name = "Mac L2";
            bindings = <
&trans         &trans         &trans         &trans         &trans         &trans         &trans         &trans         &trans         &trans         &trans         &trans
&trans         &trans         &trans         &trans         &trans         &trans         &trans         &trans         &trans         &trans         &trans         &trans
&trans         &trans         &trans         &trans         &trans         &trans         &trans         &trans         &trans         &trans         &trans         &kp LG(LS(N5))   // Enter の位置 = PrtSc → Mac: Cmd+Shift+5 (撮り方を選ぶ画面)
&trans         &trans         &trans         &trans         &trans         &trans         &trans         &trans         &trans         &trans         &trans         &trans
                                             &trans         &trans         &trans         &trans         &trans         &trans
&trans                                                                                                &trans   // ホイールのプッシュ
            >;
        };

        mac_l3_layer {
            display-name = "Mac L3";
            bindings = <
&trans         &trans         &trans         &trans         &trans         &trans         &trans         &trans         &trans         &trans         &trans         &trans
&trans         &trans         &trans         &trans         &trans         &trans         &trans         &trans         &trans         &trans         &trans         &trans
&trans         &trans         &trans         &trans         &trans         &trans         &trans         &trans         &trans         &trans         &trans         &kp LG(LS(N5))   // Enter の位置 = PrtSc → Mac: Cmd+Shift+5 (撮り方を選ぶ画面)
&trans         &trans         &trans         &trans         &trans         &trans         &trans         &trans         &trans         &trans         &trans         &trans
                                             &trans         &trans         &trans         &trans         &trans         &trans
&trans                                                                                                &trans   // ホイールのプッシュ
            >;
        };

        ios_l1_layer {
            display-name = "iOS L1";
            bindings = <
&trans         &btm_1         &btm_2         &btm_3         &btm_4         &btm_5         &trans         &trans         &trans         &trans         &trans         &trans   // ★ 2026-11-21 1〜5 = Ctrl / Cmd + で BT1〜5 (btm_1〜btm_5)
&trans         &trans         &trans         &trans         &trans         &trans         &trans         &trans         &trans         &trans         &trans         &trans
&trans         &trans         &trans         &trans         &trans         &trans         &trans         &trans         &trans         &trans         &trans         &kp LG(LS(N4))   // Enter の位置 = PrtSc → iOS: Cmd+Shift+4 (撮ってすぐ書き込み)
&trans         &trans         &trans         &trans         &trans         &trans         &trans         &trans         &trans         &trans         &trans         &trans
                                             &trans         &trans         &trans         &trans         &trans         &trans
&trans                                                                                                &trans   // ホイールのプッシュ
            >;
        };

        ios_l2_layer {
            display-name = "iOS L2";
            bindings = <
&trans         &trans         &trans         &trans         &trans         &trans         &trans         &trans         &trans         &trans         &trans         &trans
&trans         &trans         &trans         &trans         &trans         &trans         &trans         &trans         &trans         &trans         &trans         &trans
&trans         &trans         &trans         &trans         &trans         &trans         &trans         &trans         &trans         &trans         &trans         &kp LG(LS(N4))   // Enter の位置 = PrtSc → iOS: Cmd+Shift+4 (撮ってすぐ書き込み)
&trans         &trans         &trans         &trans         &trans         &trans         &trans         &trans         &trans         &trans         &trans         &trans
                                             &trans         &trans         &trans         &trans         &trans         &trans
&trans                                                                                                &trans   // ホイールのプッシュ
            >;
        };

        ios_l3_layer {
            display-name = "iOS L3";
            bindings = <
&trans         &trans         &trans         &trans         &trans         &trans         &trans         &trans         &trans         &trans         &trans         &trans
&trans         &trans         &trans         &trans         &trans         &trans         &trans         &trans         &trans         &trans         &trans         &trans
&trans         &trans         &trans         &trans         &trans         &trans         &trans         &trans         &trans         &trans         &trans         &kp LG(LS(N4))   // Enter の位置 = PrtSc → iOS: Cmd+Shift+4 (撮ってすぐ書き込み)
&trans         &trans         &trans         &trans         &trans         &trans         &trans         &trans         &trans         &trans         &trans         &trans
                                             &trans         &trans         &trans         &trans         &trans         &trans
&trans                                                                                                &trans   // ホイールのプッシュ
            >;
        };

        and_l1_layer {
            display-name = "Andr L1";
            bindings = <
&trans         &trans         &trans         &trans         &trans         &trans         &trans         &trans         &trans         &trans         &trans         &trans
&trans         &trans         &trans         &trans         &trans         &trans         &trans         &trans         &trans         &trans         &trans         &trans
&trans         &trans         &trans         &trans         &trans         &trans         &trans         &trans         &trans         &trans         &trans         &trans
&trans         &trans         &trans         &trans         &trans         &trans         &trans         &trans         &trans         &trans         &trans         &trans
                                             &trans         &trans         &trans         &trans         &trans         &trans
&trans                                                                                                &trans   // ホイールのプッシュ
            >;
        };

        and_l2_layer {
            display-name = "Andr L2";
            bindings = <
&trans         &trans         &trans         &trans         &trans         &trans         &trans         &trans         &trans         &trans         &trans         &trans
&trans         &trans         &trans         &trans         &trans         &trans         &trans         &trans         &trans         &trans         &trans         &trans
&trans         &trans         &trans         &trans         &trans         &trans         &trans         &trans         &trans         &trans         &trans         &trans
&trans         &trans         &trans         &trans         &trans         &trans         &trans         &trans         &trans         &trans         &trans         &trans
                                             &trans         &trans         &trans         &trans         &trans         &trans
&trans                                                                                                &trans   // ホイールのプッシュ
            >;
        };

        and_l3_layer {
            display-name = "Andr L3";
            bindings = <
&trans         &trans         &trans         &trans         &trans         &trans         &trans         &trans         &trans         &trans         &trans         &trans
&trans         &trans         &trans         &trans         &trans         &trans         &trans         &trans         &trans         &trans         &trans         &trans
&trans         &trans         &trans         &trans         &trans         &trans         &trans         &trans         &trans         &trans         &trans         &trans
&trans         &trans         &trans         &trans         &trans         &trans         &trans         &trans         &trans         &trans         &trans         &trans
                                             &trans         &trans         &trans         &trans         &trans         &trans
&trans                                                                                                &trans   // ホイールのプッシュ
            >;
        };

        lnx_l1_layer {
            display-name = "Lnx L1";
            bindings = <
&trans         &trans         &trans         &trans         &trans         &trans         &trans         &trans         &trans         &trans         &trans         &trans
&trans         &trans         &trans         &trans         &trans         &trans         &trans         &trans         &trans         &trans         &trans         &trans
&trans         &trans         &trans         &trans         &trans         &trans         &trans         &trans         &trans         &trans         &trans         &trans
&trans         &trans         &trans         &trans         &trans         &trans         &trans         &trans         &trans         &trans         &trans         &trans
                                             &trans         &trans         &trans         &trans         &trans         &trans
&trans                                                                                                &trans   // ホイールのプッシュ
            >;
        };

        lnx_l2_layer {
            display-name = "Lnx L2";
            bindings = <
&trans         &trans         &trans         &trans         &trans         &trans         &trans         &trans         &trans         &trans         &trans         &trans
&trans         &trans         &trans         &trans         &trans         &trans         &trans         &trans         &trans         &trans         &trans         &trans
&trans         &trans         &trans         &trans         &trans         &trans         &trans         &trans         &trans         &trans         &trans         &trans
&trans         &trans         &trans         &trans         &trans         &trans         &trans         &trans         &trans         &trans         &trans         &trans
                                             &trans         &trans         &trans         &trans         &trans         &trans
&trans                                                                                                &trans   // ホイールのプッシュ
            >;
        };

        lnx_l3_layer {
            display-name = "Lnx L3";
            bindings = <
&trans         &trans         &trans         &trans         &trans         &trans         &trans         &trans         &trans         &trans         &trans         &trans
&trans         &trans         &trans         &trans         &trans         &trans         &trans         &trans         &trans         &trans         &trans         &trans
&trans         &trans         &trans         &trans         &trans         &trans         &trans         &trans         &trans         &trans         &trans         &trans
&trans         &trans         &trans         &trans         &trans         &trans         &trans         &trans         &trans         &trans         &trans         &trans
                                             &trans         &trans         &trans         &trans         &trans         &trans
&trans                                                                                                &trans   // ホイールのプッシュ
            >;
        };

        /*
         * ★ 2026-11-15 L2 + L3 を押している間 (SETENT = 24、条件付きレイヤー)。- の位置で設定レイヤーへ入る。
         *   右手だけで設定レイヤーに入るため (2026-11-04 のユーザー指定「片側が使えなくても、もう片側だけで設定できるように」)。
         *   前は L2 + 右 Shift + - (&set_r)。右 Shift の位置が L3 になったので、同じ指の動き (L2 + 右 Shift の位置 + -) をこれで残した。
         *   ゴースト (計算): L2 と右 Shift の位置は、ほかのキーと同時に押してもゴーストが立たない。
         */
        setent_layer {
            display-name = "L2+L3";
            bindings = <
&trans         &trans         &trans         &trans         &trans         &trans         &trans         &trans         &trans         &trans         &trans         &tog SETTINGS   // - の位置 = 設定レイヤーへ
&trans         &trans         &trans         &trans         &trans         &trans         &trans         &trans         &trans         &trans         &trans         &trans
&trans         &trans         &trans         &trans         &trans         &trans         &trans         &trans         &trans         &trans         &trans         &trans
&trans         &trans         &trans         &trans         &trans         &trans         &trans         &trans         &trans         &trans         &trans         &trans
                                             &trans         &trans         &trans         &trans         &trans         &trans
&trans                                                                                                &trans   // ホイールのプッシュ
            >;
        };

        /*
         * ★ 2026-11-04 設定レイヤー (SETTINGS = 5。2026-11-15 から 25)
         *   入る: 左 = L1 + Shift + Esc の位置 / 右 = L2 + Shift + - の位置 (&set_l / &set_r)
         *     ★ 2026-11-15 右 Shift の位置は L3 になった。右手だけなら L2 + L3 (右 Shift の位置) + - (setent_layer)、または L2 + 左 Shift + -。
         *   出る: L1 / L2 / 左 Ctrl / Enter (&tog SETTINGS)。入ったままになるので、終わったら必ず出る。
         *   ほかのキーは &none。文字が打てなければ設定レイヤーにいる (OLED は "Set")。
         *   ★ 2026-11-15 ホイール (左右とも): 回す = ホイールのスクロールの速さを 1 段ずつ (下へスクロールする向き = 速く)、押し込み = 既定に戻す (&enc_spd / &tps_w)。OLED の下の行の W の数字が段。
         *   片側だけでも使えるよう、左右に同じものを置いた (左のキー = 左に効く / 右のキー = 右に効く)。
         *     左: Q=USB へ W=BT へ E=USB と BT の切り替え R=BT 消去 / A=TP 校正 S=感度を既定に戻す D=感度を下げる F=感度を上げる G=TP 復旧 / X=書き換え C=スクロールを既定に
         *     右: P=USB へ O=BT へ I=USB と BT の切り替え U=BT 消去 / ;=TP 校正 L=感度を既定に戻す J=感度を下げる K=感度を上げる H=TP 復旧 / .=書き換え ,=スクロールを既定に
         *   ★ 2026-11-11 (3 回目、ユーザー指定「設定レイヤーの TP 関連は左右とも TP がある行に全て移す」):
         *     TP の行 (A〜G / H〜;) の 5 つに、TP 校正・感度戻す・感度−・感度＋・TP 復旧を置いた。並びは Claude が決めた:
         *       ・TP 校正 (Z / /) と感度−・＋ (C V / M ,) は 1 段上へ (同じ指)。TP 復旧は TP のすぐ隣の G / H。
         *       ・感度戻す は S / L。右で設定レイヤーに入るキー (-) を押したまま L を押すと BT1 のペアリングが立つ (配線表から計算) ので、
         *         入った直後に押すことが多そうな TP 復旧ではなく、あまり押さない感度戻すを L にした。入ったら指を全部離してから押すこと。
         *       ・スクロールの速さを既定に (前は G / H) は TP の行に入らないので C / , へ (ほかのどのキーと同時に押しても、ペアリング・書き換え・BT 消去が立たない場所)。
         *         遅く・速く (親指の Alt / Space) はそのまま。
         *     ゴースト (計算、2 キー同時): TP の行のキーどうしでは何も立たない。危ないもの: 4 + A → 書き換え、A + V → BT1 ペア、S + B → BT2 ペア、
         *       5 + D → BT4 ペア / 7 + ; → 書き換え、- + L → BT1 ペア、6 + K → BT2 ペア (B・V・5・- はふだん押さない、4・7・6 はペアリングのキー)。
         *   (以下は 2026-11-11 (3 回目) より前の位置の記録)
         *   ★ 2026-11-09 B / N (ホイールの隣) に「感度を既定 (100%) に戻す」(&tps_l / &tps_r TPS_DEF) を置いた (ユーザー指定)。
         *     ゴースト (計算): B + Esc → C (左の感度を下げる)、N + - → , (右の感度を上げる) が立ちうる。書き換え・BT 消去には立たない。
         *   ★ 2026-11-11 F / J に TP 復旧 (&tpfix、試し) を置いた (ユーザー指定)。押した側の LPPS を読み直し、結果を押した側の OLED に 10 秒出す。
         *     ゴースト (計算): F・J はほかのどのキーと同時に押しても、設定レイヤーで何かするキーは立たない。
         *   ★ 2026-11-11 スクロールの速さ (&tps_s、左右共通): 左 Alt の位置 = 遅く・左 Space の位置 = 速く / 右 Space の位置 = 遅く・右 Alt の位置 = 速く /
         *     G・H = 既定 (2%) に戻す。「左のキー = 下げる / 右のキー = 上げる」は感度と同じ。
         *     位置はゴーストの計算で選んだ (ユーザーは位置を指定していない): G・H・親指の Alt・Space は、ほかのどのキーと同時に押しても
         *     ペアリング・書き換え・BT 消去が立たない (S・D・K・L は 1 キーとの同時押しで立つ組み合わせがあったので避けた)。
         *   ★ 2026-11-15 BT5 (Linux) のペアリング (&pair5) を左 5 / 右 0 に追加。BT3 = iOS (iPad から改名)、BT4 = Android (前は予備)。
         *     ゴースト (配線表から計算、2 キー同時): 5 が立つのは 4 + Q・Esc + S、0 が立つのは ; + M・BS + 右ホイール押し・N + P。
         *       ⚠ 左で入った Esc を押したまま S (感度戻す) を押すと BT5 のペアリングが立つ。入ったら一度すべてのキーから指を離すこと (前からの決まり)。
         *       5 + D は 4 (BT4 のペアリング) も立つ (前から記録あり)。0 + 6 → P (USB へ)、5 + 1 → Q (USB へ) も立つ (ふだん同時には押さない)。
         *       Ctrl はゴーストが立たない位置なので、L1〜L3 の Ctrl + 5 (BT5 へ切り替え) にゴーストはない。
         *   ★ 2026-11-11 左 1〜4 / 右 6〜9 に「ボタン一つでペアリング」(&pair1〜&pair4 = BT1 Mac / BT2 Win / BT3 iPad / BT4 予備) を置いた (ユーザー指定)。
         *     押すと、出力を BT にし、その番号を選び、その番号の登録を消して、その OS のレイヤーへ移る (設定レイヤーから出る)。
         *     右は 6 = BT1 … 9 = BT4 (数字の順。左右対称ではない)。
         *     ゴースト (計算): 入ったキーを押したまま数字を押すと危ない。左 Esc + 3 / 右 - + 8 → 書き換え (+ BT3 のペアリング)。
         *       入ったら一度すべてのキーから指を離してから数字を押すこと。
         *     2 つ同時に押すとペアリングが立つ組み合わせ: 左 2 + X・3 + V・5 + D・Tab + ホイール・Q + B・E + ホイール・R + X・T + Z・A + V・S + B /
         *       右 6 + K・7 + P・8 + M・9 + .・- + L・Y + /・U + .・I + ホイール・L + N (右は数字の並びが左と対称でないので別に計算)。
         *   Q〜R と P〜U、A〜G と ;〜H、X・C と .・, は、同じ指で同じことができるように左右対称にした (感度の−・＋だけは下の決まりのため対称でない)。
         *   感度は左右とも「左のキー = 下げる / 右のキー = 上げる」(ユーザー指定)。
         *   BT 消去は選択中の接続先 1 台分だけ (左右の間の接続は消えない)。https://zmk.dev/docs/keymaps/behaviors/bluetooth
         *   書き換え (&bootloader) と TP 校正 (&tpcalib) は押した側の半身に効く。
         *   TP 校正は、押したあと次にスティックが値を送ったときに行われる。そのときスティックに触らないこと。
         *   ★ 2026-11-11 (5 回目) 押して 1.5 秒後から 5 秒の間にスティックから値が来たとき (= ドリフトしている) だけ校正する。
         *     来なければ何もしない (ドリフトしていないときに押すと、次に触った力を 0 にしてしまうため)。結果は押した側の OLED に
         *     "CAL ok" / "CAL skip" / "CAL wait!" (src/behaviors/behavior_tp_calib_local.c)。押したら 7 秒ほど触らない。
         *   https://zmk.dev/docs/keymaps/behaviors/layers
         */
        settings_layer {
            display-name = "Set";
            bindings = <
&none          &pair1         &pair2         &pair3         &pair4         &pair5           &pair1         &pair2         &pair3         &pair4         &pair5         &none   // 左 1〜5 / 右 6〜0 = BT1〜BT5 をペアリング (2026-11-11。BT5 = 左 5 / 右 0 は 2026-11-15)
&none          &out OUT_USB   &out OUT_BLE   &out OUT_TOG   &bt BT_CLR     &none            &none          &bt BT_CLR     &out OUT_TOG   &out OUT_BLE   &out OUT_USB   &none
&tog SETTINGS  &tpcalib       &tps_l TPS_DEF &tps_l TPS_DN  &tps_l TPS_UP  &tpfix           &tpfix         &tps_r TPS_DN  &tps_r TPS_UP  &tps_r TPS_DEF &tpcalib       &tog SETTINGS   // ★ 2026-11-11 (2 回目) TP の行: 左 A=TP 校正 S=感度戻す D=感度− F=感度＋ G=TP 復旧 / 右 H=TP 復旧 J=感度− K=感度＋ L=感度戻す ;=TP 校正。左 Ctrl / Enter の位置 = 設定レイヤーから出る
&none          &none          &bootloader    &tps_s TPS_DEF &none          &none            &none          &none          &tps_s TPS_DEF &bootloader    &none          &none   // X / . = 書き換え / C / , = スクロールの速さを既定に (2026-11-11 (2 回目) G・H から)
                                             &tps_s TPS_DN  &tps_s TPS_UP  &tog SETTINGS    &tog SETTINGS  &tps_s TPS_DN  &tps_s TPS_UP   // L1 / L2 の位置 = 設定レイヤーから出る / 左右とも Alt と Space の位置 = スクロールを遅く・速く (2026-11-11)
&tps_w TPS_DEF                                                                                        &tps_w TPS_DEF   // ホイールのプッシュ = ホイールの速さを既定に (2026-11-15。前は &none)
            >;
            /* ★ 2026-11-15 設定レイヤーではホイールを回すとホイールの速さが変わる (&enc_spd。前は下のレイヤーと同じ = スクロール) */
            sensor-bindings = <&enc_spd &enc_spd>;
        };

        /*
         * ★ 2026-11-15 ドラッグレイヤー (DRAG = 6。同じ日に OS のレイヤーを足して 26)。L1〜L3 のクリック (&dragclk) を押している間だけ重なる。
         *   キーはすべて &trans (下のレイヤーと同じ)。このレイヤーがあるときは、スティックがスクロール (★ 2026-11-21 上下 / 左右) ではなく
         *   カーソルになる (split54tp_right.overlay の tp_drag)。OLED のレイヤー名は "Drag" になる。
         */
        drag_layer {
            display-name = "Drag";
            bindings = <
&trans         &trans         &trans         &trans         &trans         &trans           &trans         &trans         &trans         &trans         &trans         &trans
&trans         &trans         &trans         &trans         &trans         &trans           &trans         &trans         &trans         &trans         &trans         &trans
&trans         &trans         &trans         &trans         &trans         &trans           &trans         &trans         &trans         &trans         &trans         &trans
&trans         &trans         &trans         &trans         &trans         &trans           &trans         &trans         &trans         &trans         &trans         &trans
                                             &trans         &trans         &trans           &trans         &trans         &trans
&trans                                                                                                &trans   // ホイールのプッシュ
            >;
        };

        /*
         * ZMK Studio 用の予約レイヤー。
         * 通常ビルドでは無視され、Studio 有効ビルドでのみ使えるようになる。
         * devicetree で確保した数を超えるレイヤーは Studio では追加できないため、
         * あらかじめ余分に用意しておく。
         * https://zmk.dev/docs/features/studio#including-extra-layers
         */
        extra1 { status = "reserved"; };
        extra2 { status = "reserved"; };
    };
};
